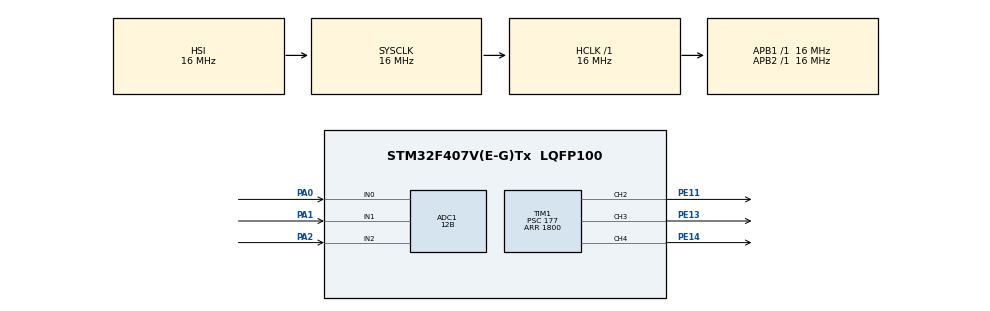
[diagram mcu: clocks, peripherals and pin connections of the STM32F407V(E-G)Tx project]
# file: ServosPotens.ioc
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ADC1.Channel-0\#ChannelRegularConversion=ADC_CHANNEL_0
ADC1.Channel-1\#ChannelRegularConversion=ADC_CHANNEL_1
ADC1.Channel-2\#ChannelRegularConversion=ADC_CHANNEL_2
ADC1.ClockPrescaler=ADC_CLOCK_SYNC_PCLK_DIV2
ADC1.ContinuousConvMode=ENABLE
ADC1.DMAContinuousRequests=ENABLE
ADC1.DataAlign=ADC_DATAALIGN_RIGHT
ADC1.DiscontinuousConvMode=DISABLE
ADC1.EOCSelection=ADC_EOC_SINGLE_CONV
ADC1.EnableAnalogWatchDog=false
ADC1.ExternalTrigConv=ADC_SOFTWARE_START
ADC1.ExternalTrigConvEdge=ADC_EXTERNALTRIGCONVEDGE_NONE
ADC1.InjNumberOfConversion=0
ADC1.NbrOfConversion=3
ADC1.NbrOfConversionFlag=1
ADC1.Rank-0\#ChannelRegularConversion=1
ADC1.Rank-1\#ChannelRegularConversion=2
ADC1.Rank-2\#ChannelRegularConversion=3
ADC1.Resolution=ADC_RESOLUTION_12B
ADC1.SamplingTime-0\#ChannelRegularConversion=ADC_SAMPLETIME_480CYCLES
ADC1.SamplingTime-1\#ChannelRegularConversion=ADC_SAMPLETIME_480CYCLES
ADC1.SamplingTime-2\#ChannelRegularConversion=ADC_SAMPLETIME_480CYCLES
ADC1.ScanConvMode=ENABLE
ADC1.master=1
Dma.ADC1.0.Direction=DMA_PERIPH_TO_MEMORY
Dma.ADC1.0.FIFOMode=DMA_FIFOMODE_DISABLE
Dma.ADC1.0.Instance=DMA2_Stream0
Dma.ADC1.0.MemDataAlignment=DMA_MDATAALIGN_HALFWORD
Dma.ADC1.0.MemInc=DMA_MINC_ENABLE
Dma.ADC1.0.Mode=DMA_CIRCULAR
Dma.ADC1.0.PeriphDataAlignment=DMA_PDATAALIGN_HALFWORD
Dma.ADC1.0.PeriphInc=DMA_PINC_DISABLE
Dma.ADC1.0.Priority=DMA_PRIORITY_LOW
Dma.Request0=ADC1
Mcu.Family=STM32F4
Mcu.Name=STM32F407V(E-G)Tx
Mcu.Package=LQFP100
NVIC.DMA2_Stream0_IRQn=true\:0\:0\:false\:false\:true\:true
NVIC.PriorityGroup=NVIC_PRIORITYGROUP_4
PA0-WKUP.Signal=ADCx_IN0
PA1.Signal=ADCx_IN1
PA2.Signal=ADCx_IN2
PE11.Signal=S_TIM1_CH2
PE13.Signal=S_TIM1_CH3
PE14.Signal=S_TIM1_CH4
ProjectManager.HeapSize=0x200
ProjectManager.StackSize=0x400
ProjectManager.TargetToolchain=TrueSTUDIO
RCC.AHBFreq_Value=16000000
RCC.APB1Freq_Value=16000000
RCC.APB2Freq_Value=16000000
RCC.CortexFreq_Value=16000000
RCC.HSE_VALUE=25000000
RCC.HSI_VALUE=16000000
RCC.LSE_VALUE=32768
RCC.SYSCLKFreq_VALUE=16000000
RCC.VCOOutputFreq_Value=192000000
SH.ADCx_IN0.0=ADC1_IN0,IN0
SH.ADCx_IN1.0=ADC1_IN1,IN1
SH.ADCx_IN2.0=ADC1_IN2,IN2
SH.S_TIM1_CH2.0=TIM1_CH2,PWM Generation2 CH2
SH.S_TIM1_CH3.0=TIM1_CH3,PWM Generation3 CH3
SH.S_TIM1_CH4.0=TIM1_CH4,PWM Generation4 CH4
TIM1.Channel-PWM\ Generation2\ CH2=TIM_CHANNEL_2
TIM1.Channel-PWM\ Generation3\ CH3=TIM_CHANNEL_3
TIM1.Channel-PWM\ Generation4\ CH4=TIM_CHANNEL_4
TIM1.Period=1800
TIM1.Prescaler=177
TIM1.Pulse-PWM\ Generation3\ CH3=0
VP_TIM1_VS_ClockSourceINT.Mode=Internal
board=ServosPotens

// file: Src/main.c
/**
  ******************************************************************************
  * File Name          : main.c
  * Description        : Main program body
  ******************************************************************************
  ** This notice applies to any and all portions of this file
  * that are not between comment pairs USER CODE BEGIN and
  * USER CODE END. Other portions of this file, whether
  * inserted by the user or by software development tools
  * are owned by their respective copyright owners.
  *
  * COPYRIGHT(c) 2018 STMicroelectronics
  *
  * Redistribution and use in source and binary forms, with or without modification,
  * are permitted provided that the following conditions are met:
  *   1. Redistributions of source code must retain the above copyright notice,
  *      this list of conditions and the following disclaimer.
  *   2. Redistributions in binary form must reproduce the above copyright notice,
  *      this list of conditions and the following disclaimer in the documentation
  *      and/or other materials provided with the distribution.
  *   3. Neither the name of STMicroelectronics nor the names of its contributors
  *      may be used to endorse or promote products derived from this software
  *      without specific prior written permission.
  *
  * THIS SOFTWARE IS PROVIDED BY THE COPYRIGHT HOLDERS AND CONTRIBUTORS "AS IS"
  * AND ANY EXPRESS OR IMPLIED WARRANTIES, INCLUDING, BUT NOT LIMITED TO, THE
  * IMPLIED WARRANTIES OF MERCHANTABILITY AND FITNESS FOR A PARTICULAR PURPOSE ARE
  * DISCLAIMED. IN NO EVENT SHALL THE COPYRIGHT HOLDER OR CONTRIBUTORS BE LIABLE
  * FOR ANY DIRECT, INDIRECT, INCIDENTAL, SPECIAL, EXEMPLARY, OR CONSEQUENTIAL
  * DAMAGES (INCLUDING, BUT NOT LIMITED TO, PROCUREMENT OF SUBSTITUTE GOODS OR
  * SERVICES; LOSS OF USE, DATA, OR PROFITS; OR BUSINESS INTERRUPTION) HOWEVER
  * CAUSED AND ON ANY THEORY OF LIABILITY, WHETHER IN CONTRACT, STRICT LIABILITY,
  * OR TORT (INCLUDING NEGLIGENCE OR OTHERWISE) ARISING IN ANY WAY OUT OF THE USE
  * OF THIS SOFTWARE, EVEN IF ADVISED OF THE POSSIBILITY OF SUCH DAMAGE.
  *
  ******************************************************************************
  */

#include "main.h"
#include "stm32f4xx_hal.h"
#include "adc.h"
#include "dma.h"
#include "tim.h"
#include "gpio.h"

/* USER CODE BEGIN PV */
/* Private variables ---------------------------------------------------------*/

/* USER CODE END PV */

void SystemClock_Config(void);

/* USER CODE BEGIN PFP */
/* Private function prototypes -----------------------------------------------*/

/* USER CODE END PFP */

/* USER CODE BEGIN 0 */
uint16_t lectura_adc[3];
/* USER CODE END 0 */

int main(void)
{

  /* MCU Configuration----------------------------------------------------------*/

  /* Reset of all peripherals, Initializes the Flash interface and the Systick. */
  HAL_Init();

  /* Configure the system clock */
  SystemClock_Config();

  /* Initialize all configured peripherals */
  MX_GPIO_Init();
  MX_DMA_Init();
  MX_ADC1_Init();
  MX_TIM1_Init();

  /* USER CODE BEGIN 2 */

  HAL_TIM_PWM_Start(&htim1,TIM_CHANNEL_2);
  HAL_TIM_PWM_Start(&htim1,TIM_CHANNEL_3);
  HAL_TIM_PWM_Start(&htim1,TIM_CHANNEL_4);
  HAL_ADC_Start_DMA(&hadc1,(uint32_t*)lectura_adc,3);

  /* USER CODE END 2 */

  /* Infinite loop */
  while (1)
  {

  /* USER CODE BEGIN 3 */

	  HAL_ADC_Start(&hadc1);
	  int signal1=(lectura_adc[0]*4/91)+45;
	  int signal2=(lectura_adc[1]*4/91)+45;
	  int signal3=(lectura_adc[2]*4/91)+45;
	 	   	__HAL_TIM_SET_COMPARE(&htim1,TIM_CHANNEL_2,signal1);
	 	   __HAL_TIM_SET_COMPARE(&htim1,TIM_CHANNEL_3,signal2);
	 	  __HAL_TIM_SET_COMPARE(&htim1,TIM_CHANNEL_4,signal3);

  }
  /* USER CODE END 3 */

}

/** System Clock Configuration
*/
void SystemClock_Config(void)
{

  RCC_OscInitTypeDef RCC_OscInitStruct;
  RCC_ClkInitTypeDef RCC_ClkInitStruct;

    /**Configure the main internal regulator output voltage
    */
  __HAL_RCC_PWR_CLK_ENABLE();

  __HAL_PWR_VOLTAGESCALING_CONFIG(PWR_REGULATOR_VOLTAGE_SCALE1);

    /**Initializes the CPU, AHB and APB busses clocks
    */
  RCC_OscInitStruct.OscillatorType = RCC_OSCILLATORTYPE_HSI;
  RCC_OscInitStruct.HSIState = RCC_HSI_ON;
  RCC_OscInitStruct.HSICalibrationValue = 16;
  RCC_OscInitStruct.PLL.PLLState = RCC_PLL_NONE;
  if (HAL_RCC_OscConfig(&RCC_OscInitStruct) != HAL_OK)
  {
    _Error_Handler(__FILE__, __LINE__);
  }

    /**Initializes the CPU, AHB and APB busses clocks
    */
  RCC_ClkInitStruct.ClockType = RCC_CLOCKTYPE_HCLK|RCC_CLOCKTYPE_SYSCLK
                              |RCC_CLOCKTYPE_PCLK1|RCC_CLOCKTYPE_PCLK2;
  RCC_ClkInitStruct.SYSCLKSource = RCC_SYSCLKSOURCE_HSI;
  RCC_ClkInitStruct.AHBCLKDivider = RCC_SYSCLK_DIV1;
  RCC_ClkInitStruct.APB1CLKDivider = RCC_HCLK_DIV1;
  RCC_ClkInitStruct.APB2CLKDivider = RCC_HCLK_DIV1;

  if (HAL_RCC_ClockConfig(&RCC_ClkInitStruct, FLASH_LATENCY_0) != HAL_OK)
  {
    _Error_Handler(__FILE__, __LINE__);
  }

    /**Configure the Systick interrupt time
    */
  HAL_SYSTICK_Config(HAL_RCC_GetHCLKFreq()/1000);

    /**Configure the Systick
    */
  HAL_SYSTICK_CLKSourceConfig(SYSTICK_CLKSOURCE_HCLK);

  /* SysTick_IRQn interrupt configuration */
  HAL_NVIC_SetPriority(SysTick_IRQn, 0, 0);
}

void _Error_Handler(char * file, int line)
{
  while(1)
  {
  }
}

/************************ (C) COPYRIGHT STMicroelectronics *****END OF FILE****/
